# MCASP0_CFG register map
Vendor: Texas Instruments
Peripheral module from a debugger description file (folder am65x).
Registers are 32-bit, read-write, reset 0x0 unless marked. A register's access mark holds for its fields unless they carry their own. Offsets are as the file gives them; lines under a group give offsets from that group; [hi:lo] are bit positions; {n}, {i} and the like mark numbered series; 'fields as' and 'values as' point back to an identical list; <NAME> marks a mode.

## MCASP0_CFG
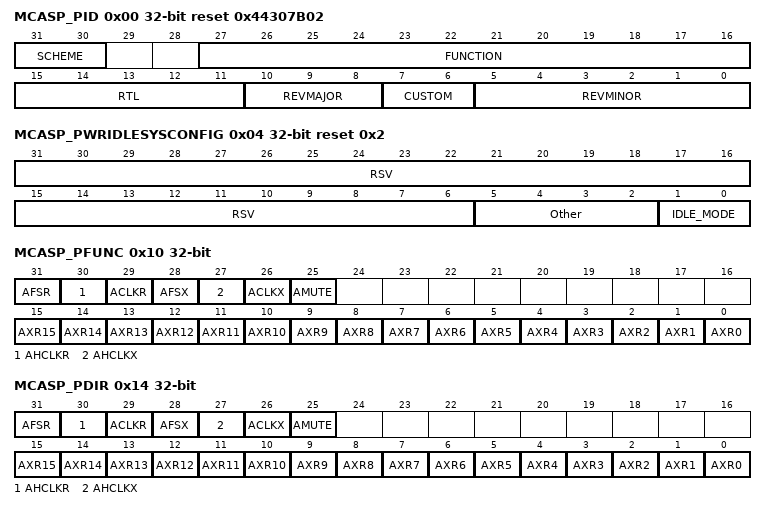
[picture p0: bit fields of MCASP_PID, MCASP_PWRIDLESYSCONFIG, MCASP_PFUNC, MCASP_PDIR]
0x00 MCASP_PID ro reset 0x44307B02
  [31:30] SCHEME
  [27:16] FUNCTION — McASP
  [15:11] RTL
  [10:8] REVMAJOR
  [7:6] CUSTOM — non-custom
  [5:0] REVMINOR
0x04 MCASP_PWRIDLESYSCONFIG access per field reset 0x2 — Power Idle SYSCONFIG register.
  [31:6] RSV ro — Reserved as per PDR 35
  [5:2] Other rw — Reserved for future expansion
  [1:0] IDLE_MODE rw
0x10 MCASP_PFUNC
  [31] AFSR — AFSR PFUNC 31
  [30] AHCLKR — AHCLKR PFUNC 30
  [29] ACLKR — ACLKR PFUNC 29
  [28] AFSX — AFSX PFUNC 28
  [27] AHCLKX — AHCLKX PFUNC 27
  [26] ACLKX — ACLKX PFUNC 26
  [25] AMUTE — AMUTE PFUNC 25
  [n] AXR{n} (n=0..15) — AXR PFUNC BIT {n}
0x14 MCASP_PDIR
  [31] AFSR — AFSR PDIR 31
  [30] AHCLKR — AHCLKR PDIR 30
  [29] ACLKR — ACLKR PDIR 29
  [28] AFSX — AFSX PDIR 28
  [27] AHCLKX — AHCLKX PDIR 27
  [26] ACLKX — ACLKX PDIR 26
  [25] AMUTE — AMUTE PDIR 25
  [n] AXR{n} (n=0..15) — AXR PDIR BIT {n}
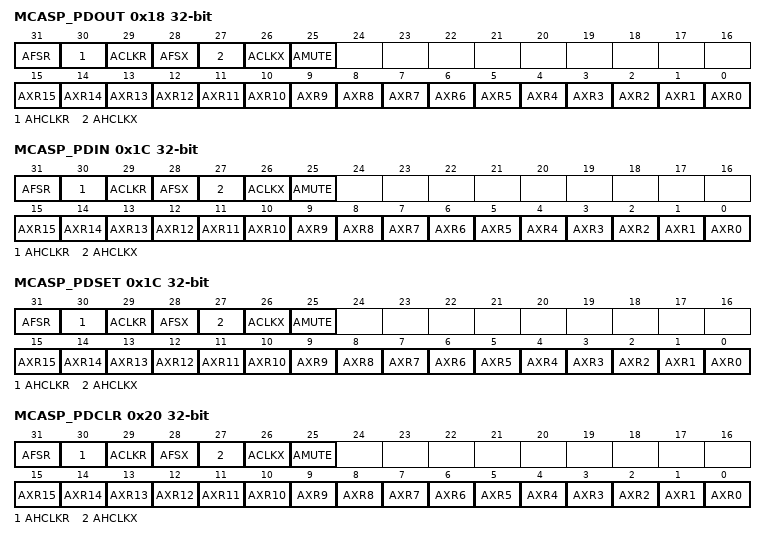
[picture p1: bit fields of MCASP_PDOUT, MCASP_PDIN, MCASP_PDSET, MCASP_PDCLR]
0x18 MCASP_PDOUT
  [31] AFSR — AFSR PDOUT 31
  [30] AHCLKR — AHCLKR PDOUT 30
  [29] ACLKR — ACLKR PDOUT 29
  [28] AFSX — AFSX PDOUT 28
  [27] AHCLKX — AHCLKX PDOUT 27
  [26] ACLKX — ACLKX PDOUT 26
  [25] AMUTE — AMUTE PDOUT 25
  [n] AXR{n} (n=0..15) — AXR PDOUT BIT {n}
0x1C MCASP_PDIN ro — The pin data input register (PDIN) holds the I/O pin state of each of the McASP pins. PDIN allows the actual value of the pin to be read, regardless of the state of PFUNC and PDIR.
  [31] AFSR — AFSR PDIN 31
  [30] AHCLKR — AHCLKR PDIN 30
  [29] ACLKR — ACLKR PDIN 29
  [28] AFSX — AFSX PDIN 28
  [27] AHCLKX — AHCLKX PDIN 27
  [26] ACLKX — ACLKX PDIN 26
  [25] AMUTE — AMUTE PDIN 25
  [n] AXR{n} (n=0..15) — AXR PDIN BIT {n}
0x1C MCASP_PDSET wo — The pin data set register (PDSET) is an alias of the pin data output register (PDOUT) for writes only. Writing a 1 to the PDSET bit sets the corresponding bit in PDOUT and, if PFUNC = 1 (GPIO function) and PDIR = 1 (output), drives a logic high on the pin.
  [31] AFSR — AFSR PDSET 31
  [30] AHCLKR — AHCLKR PDSET 30
  [29] ACLKR — ACLKR PDSET 29
  [28] AFSX — AFSX PDSET 28
  [27] AHCLKX — AHCLKX PDSET 27
  [26] ACLKX — ACLKX PDSET 26
  [25] AMUTE — AMUTE PDSET 25
  [n] AXR{n} (n=0..15) — AXR PDSET BIT {n}
0x20 MCASP_PDCLR — The pin data clear register (PDCLR) is an alias of the pin data output register (PDOUT) for writes only. Writing a 1 to the PDCLR bit clears the corresponding bit in PDOUT and, if PFUNC = 1 (GPIO function) and PDIR = 1 (output), drives a logic low on the pin.
  [31] AFSR — AFSR PDCLR 31
  [30] AHCLKR — AHCLKR PDCLR 30
  [29] ACLKR — ACLKR PDCLR 29
  [28] AFSX — AFSX PDCLR 28
  [27] AHCLKX — AHCLKX PDCLR 27
  [26] ACLKX — ACLKX PDCLR 26
  [25] AMUTE — AMUTE PDCLR 25
  [n] AXR{n} (n=0..15) — AXR PDCLR BIT {n}
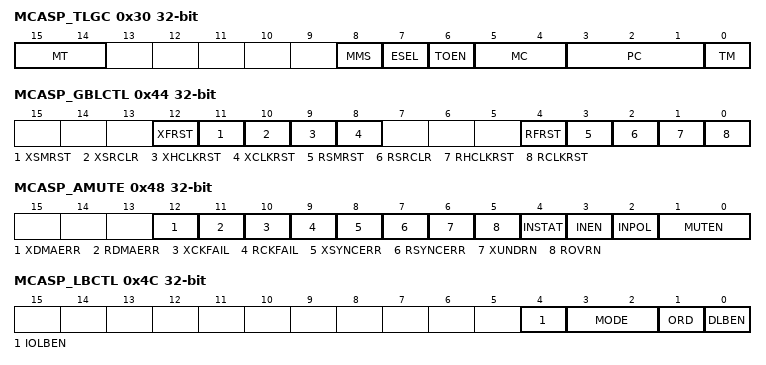
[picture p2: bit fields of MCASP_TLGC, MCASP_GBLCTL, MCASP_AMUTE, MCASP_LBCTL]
0x30 MCASP_TLGC — for IODFT
  [15:14] MT — MISR on/off trigger command
  [8] MMS — Source of MISR input
  [7] ESEL — Output enable select
  [6] TOEN — Test output enable control
  [5:4] MC — States of MISR
  [3:1] PC — Pattern code
  [0] TM — Tie high; do not write to this bit
0x34 MCASP_TLMR — for IODFT
  [31:0] TLMR — Contains test result signature
0x38 MCASP_TLEC — for IODFT
  [31:0] TLEC — Contains number of cycles during which MISR sig will be accumulated
0x44 MCASP_GBLCTL
  [12] XFRST — Frame sync generator reset
  [11] XSMRST — XMT state machine reset
  [10] XSRCLR — XMT serializer clear
  [9] XHCLKRST — XMT High Freq clk Divider
  [8] XCLKRST — XMT clock divder reset
  [4] RFRST — Frame sync generator reset
  [3] RSMRST — RCV state machine reset
  [2] RSRCLR — RCV serializer clear
  [1] RHCLKRST — RCV High Freq clk Divider
  [0] RCLKRST — RCV clock divder reset
0x48 MCASP_AMUTE access per field
  [12] XDMAERR rw — MUTETXDMAERR occur
  [11] RDMAERR rw — MUTERXDMAERR occur
  [10] XCKFAIL rw — XMT bad clock
  [9] RCKFAIL rw — RCV bad clock
  [8] XSYNCERR rw — XMT unexpected FS
  [7] RSYNCERR rw — RCV unexpected FS
  [6] XUNDRN rw — XMT underrun occurs
  [5] ROVRN rw — RCV overun occurs
  [4] INSTAT ro — status of mute in pin
  [3] INEN rw — drive AMUTE active on mute in active
  [2] INPOL rw — Mute input polarity
  [1:0] MUTEN rw — AMUTE pin enable
0x4C MCASP_LBCTL
  [4] IOLBEN — IO loopback enable
  [3:2] MODE — Loop back clock source generator
  [1] ORD — Loopback order
  [0] DLBEN — Loop back mode
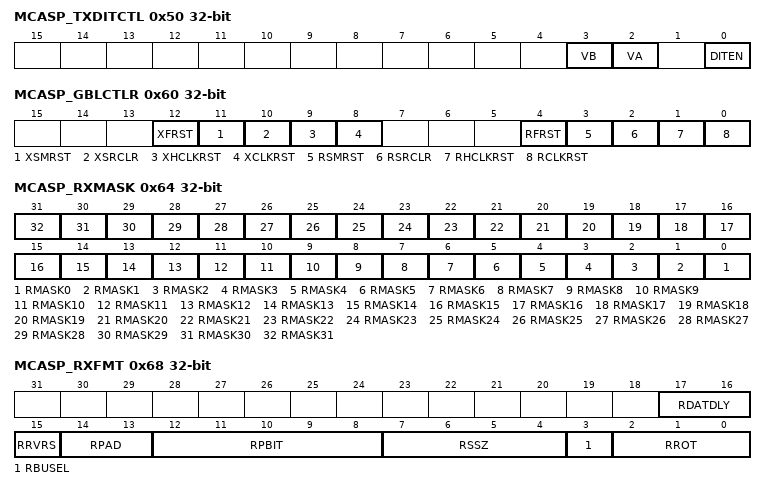
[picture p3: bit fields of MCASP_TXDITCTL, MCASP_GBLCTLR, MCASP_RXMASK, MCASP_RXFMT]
0x50 MCASP_TXDITCTL
  [3] VB — Valib bit for odd TDM
  [2] VA — Valib bit for even TDM
  [0] DITEN — XMT DIT Mode Enable
0x60 MCASP_GBLCTLR access per field
  [12] XFRST ro — Frame sync generator reset
  [11] XSMRST ro — XMT state machine reset
  [10] XSRCLR ro — XMT serializer clear
  [9] XHCLKRST ro — XMT High Freq clk Divider
  [8] XCLKRST ro — XMT clock divder reset
  [4] RFRST rw — Frame sync generator reset
  [3] RSMRST rw — RCV state machine reset
  [2] RSRCLR rw — RCV serializer clear
  [1] RHCLKRST rw — RCV High Freq clk Divider
  [0] RCLKRST rw — RCV clock divder reset
0x64 MCASP_RXMASK
  [n] RMASK{n} (n=0..31) — RMASK BIT {n}
0x68 MCASP_RXFMT
  [17:16] RDATDLY — RCV Frame sync delay
  [15] RRVRS — RCV serial stream bit order
  [14:13] RPAD — Pad value
  [12:8] RPBIT — Pad bit position
  [7:4] RSSZ — RCV slot Size
  [3] RBUSEL — Write to RBUF using CPU/DMA
  [2:0] RROT — Right Rotate Value
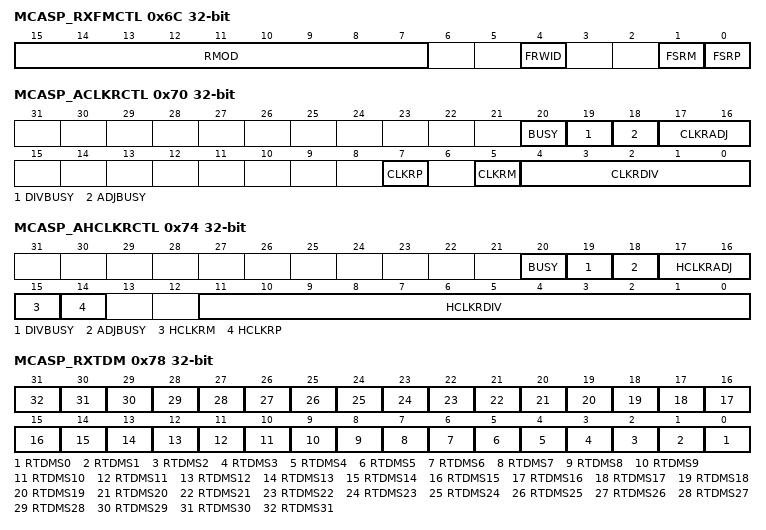
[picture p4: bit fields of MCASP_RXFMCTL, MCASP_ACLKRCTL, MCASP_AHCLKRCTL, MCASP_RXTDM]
0x6C MCASP_RXFMCTL
  [15:7] RMOD — RCV Frame sync mode
  [4] FRWID — RCV Frame sync Duration
  [1] FSRM — RCV frame sync External
  [0] FSRP — RCV Frame sync Polarity
0x70 MCASP_ACLKRCTL access per field
  [20] BUSY rw — Status: logical OR of DIVBUSY, ADJBUSY
  [19] DIVBUSY rw — Status: divide ratio change in progress?
  [18] ADJBUSY rw — Status: one-shot adjustment in progress?
  [17:16] CLKRADJ wo — CLKRDIV one-shot adjustment
  [7] CLKRP rw — RCV Clock Polarity
  [5] CLKRM rw — RCV clock source
  [4:0] CLKRDIV rw — RCV clock devide ratio
0x74 MCASP_AHCLKRCTL access per field
  [20] BUSY rw — Status: logical OR of DIVBUSY, ADJBUSY
  [19] DIVBUSY rw — Status: divide ratio change in progress?
  [18] ADJBUSY rw — Status: one-shot adjustment in progress?
  [17:16] HCLKRADJ wo — HCLKRDIV one-shot adjustment
  [15] HCLKRM rw — High Freq RCV clock Source
  [14] HCLKRP rw — High Freq clock Polarity Before diviser
  [11:0] HCLKRDIV rw — RCV clock Divide Ratio
0x78 MCASP_RXTDM
  [n] RTDMS{n} (n=0..31) — RCV mode during TDM time slot {n}
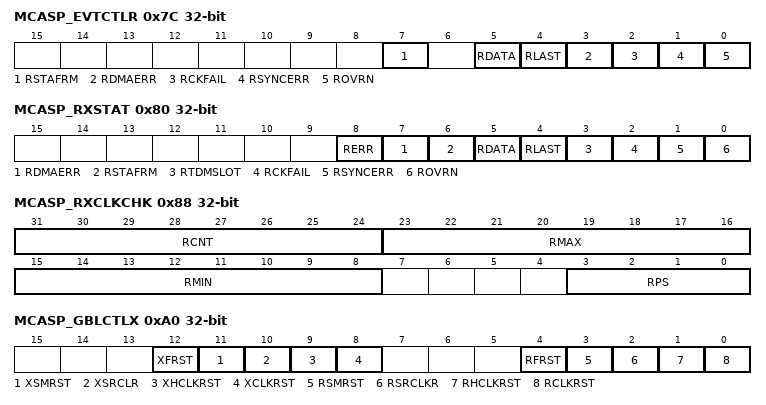
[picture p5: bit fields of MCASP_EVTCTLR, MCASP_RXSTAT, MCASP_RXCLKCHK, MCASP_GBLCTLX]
0x7C MCASP_EVTCTLR
  [7] RSTAFRM — RCV Start of Frame Interrupt
  [5] RDATA — RCV Data Interrupt
  [4] RLAST — RCV Last Slot Interrupt
  [3] RDMAERR — RCV DMA Bus Error
  [2] RCKFAIL — Bad Clock Interrupt
  [1] RSYNCERR — RCV Unexpected FSR Interrupt
  [0] ROVRN — RCV Underrun Flag
0x80 MCASP_RXSTAT
  [8] RERR — RCV Error
  [7] RDMAERR — RCV DMA bus error
  [6] RSTAFRM — Start of Frame-RCV
  [5] RDATA — Data Ready Flag
  [4] RLAST — Last Slot Interrupt Flag
  [3] RTDMSLOT — EvenOdd Slot
  [2] RCKFAIL — Bad Transmit Flag
  [1] RSYNCERR — Unexpected RCV Frame sync flag
  [0] ROVRN — RCV Underrun Flag
0x84 MCASP_RXTDMSLOT ro
  [9:0] RSLOTCNT — Current RCV time slot count
0x88 MCASP_RXCLKCHK access per field
  [31:24] RCNT ro — RCV clock count value
  [23:16] RMAX rw — RCV clock maximum boundary
  [15:8] RMIN rw — RCV clock minimum boundary
  [3:0] RPS rw — RCV clock check prescaler
0x8C MCASP_REVTCTL
  [0] RDATDMA — RCV data DMA request
0xA0 MCASP_GBLCTLX access per field
  [12] XFRST rw — Frame sync generator reset
  [11] XSMRST rw — XMT state machine reset
  [10] XSRCLR rw — XMT serializer clear
  [9] XHCLKRST rw — XMT High Freq clk Divider
  [8] XCLKRST rw — XMT clock divder reset
  [4] RFRST ro — Frame sync generator reset
  [3] RSMRST ro — RCV state machine reset
  [2] RSRCLKR ro — RCV serializer clear
  [1] RHCLKRST ro — RCV High Freq clk Divider
  [0] RCLKRST ro — RCV clock divder reset
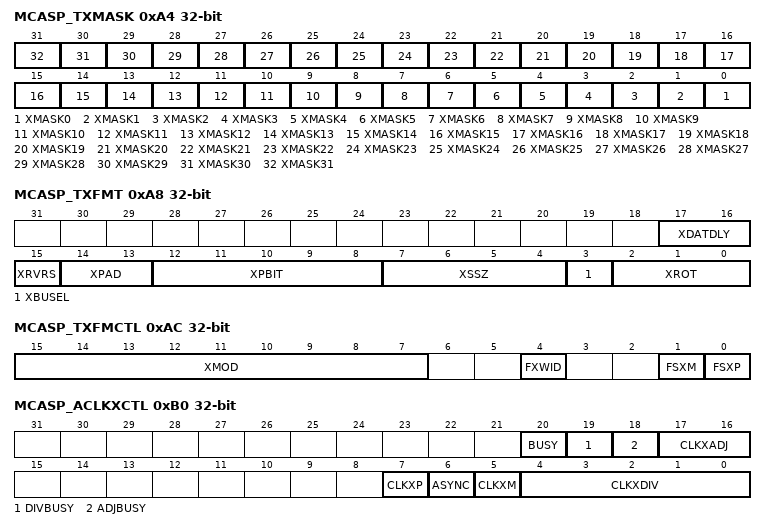
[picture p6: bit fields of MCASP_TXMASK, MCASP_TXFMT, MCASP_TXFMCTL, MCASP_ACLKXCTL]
0xA4 MCASP_TXMASK
  [n] XMASK{n} (n=0..31) — XMASK BIT {n}
0xA8 MCASP_TXFMT
  [17:16] XDATDLY — XMT Frame sync delay
  [15] XRVRS — XMT serial stream bit order
  [14:13] XPAD — Pad value
  [12:8] XPBIT — Pad bit position
  [7:4] XSSZ — XMT slot Size
  [3] XBUSEL — Write to XBUF using CPU/DMA
  [2:0] XROT — Right Rotate Value
0xAC MCASP_TXFMCTL
  [15:7] XMOD — XMT Frame sync mode
  [4] FXWID — XMT Frame sync Duration
  [1] FSXM — XMT frame sync External
  [0] FSXP — XMT Frame sync Polarity
0xB0 MCASP_ACLKXCTL access per field
  [20] BUSY rw — Status: logical OR of DIVBUSY, ADJBUSY
  [19] DIVBUSY rw — Status: divide ratio change in progress?
  [18] ADJBUSY rw — Status: one-shot adjustment in progress?
  [17:16] CLKXADJ wo — CLKXDIV one-shot adjustment
  [7] CLKXP rw — XMT Clock Polarity
  [6] ASYNC rw — XMT/RCV operation sync /Async
  [5] CLKXM rw — XMT clock source
  [4:0] CLKXDIV rw — XMT clock devide ratio
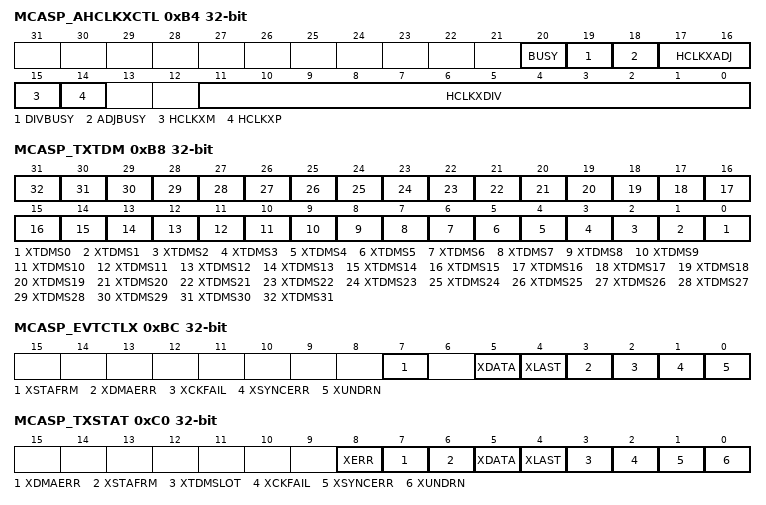
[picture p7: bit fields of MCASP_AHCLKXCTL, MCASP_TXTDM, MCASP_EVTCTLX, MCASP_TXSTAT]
0xB4 MCASP_AHCLKXCTL access per field
  [20] BUSY rw — Status: logical OR of DIVBUSY, ADJBUSY
  [19] DIVBUSY rw — Status: divide ratio change in progress?
  [18] ADJBUSY rw — Status: one-shot adjustment in progress?
  [17:16] HCLKXADJ wo — HCLKXDIV one-shot adjustment
  [15] HCLKXM rw — High Freq XMT clock Source
  [14] HCLKXP rw — High Freq clock Polarity Before diviser
  [11:0] HCLKXDIV rw — XMT clock Divide Ratio
0xB8 MCASP_TXTDM
  [n] XTDMS{n} (n=0..31) — XMT mode during TDM time slot {n}
0xBC MCASP_EVTCTLX
  [7] XSTAFRM — XMT Start of Frame Interrupt
  [5] XDATA — XMT Data Interrupt
  [4] XLAST — XMT Last Slot Interrupt
  [3] XDMAERR — XMT DMA Bus Error
  [2] XCKFAIL — Bad Clock Interrupt
  [1] XSYNCERR — XMT Unexpected FSR Interrupt
  [0] XUNDRN — XMT Underrun Interrupt
0xC0 MCASP_TXSTAT
  [8] XERR — XMT Error
  [7] XDMAERR — XMT DMA bus error
  [6] XSTAFRM — Start of Frame-XMT
  [5] XDATA — Data Ready Flag
  [4] XLAST — Last Slot Interrupt Flag
  [3] XTDMSLOT — EvenOdd Slot
  [2] XCKFAIL — Bad Transmit Flag
  [1] XSYNCERR — Unexpected XMT Frame sync flag
  [0] XUNDRN — XMT Underrun Flag
0xC4 MCASP_TXTDMSLOT ro
  [9:0] XSLOTCNT — Current XMT time slot count during reset the value of this register is 0b0101111111 [0x17f] and after reset 0
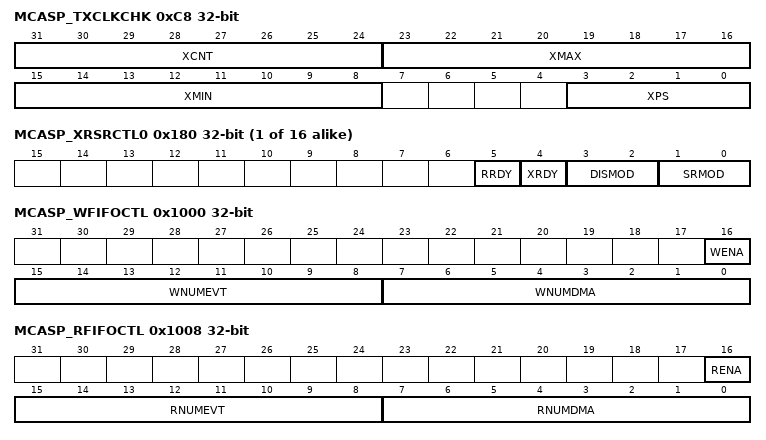
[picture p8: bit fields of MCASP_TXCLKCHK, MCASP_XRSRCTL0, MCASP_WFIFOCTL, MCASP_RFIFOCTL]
0xC8 MCASP_TXCLKCHK access per field
  [31:24] XCNT ro — XMT clock count value
  [23:16] XMAX rw — XMT clock maximum boundary
  [15:8] XMIN rw — XMT clock minimum boundary
  [3:0] XPS rw — XMT clock check prescaler
0xCC MCASP_XEVTCTL
  [0] XDATDMA — XMT data DMA request
0xD0 MCASP_CLKADJEN
  [0] ENABLE — One-shot clock adjust enable
0x100 MCASP_DITCSRA0
  [31:0] DITCSRA0 — Left [Even TDM slot ] Channel status
0x104 MCASP_DITCSRA1
  [31:0] DITCSRA1 — Left [Even TDM slot ] Channel status
0x108 MCASP_DITCSRA2
  [31:0] DITCSRA2 — Left [Even TDM slot ] Channel status Register
0x10C MCASP_DITCSRA3
  [31:0] DITCSRA3 — Left [Even TDM slot ] Channel status Register
0x110 MCASP_DITCSRA4
  [31:0] DITCSRA4 — Left [Even TDM slot ] Channel status
0x114 MCASP_DITCSRA5
  [31:0] DITCSRA5 — Left [Even TDM slot ] Channel status
{0x118+4i} MCASP_DITCSRB{i} (i=0..5)
  [31:0] DITCSRB{i} — Right [odd TDM slot ] Channel status
{0x130+4i} MCASP_DITUDRA{i} (i=0..5)
  [31:0] DITUDRA{i} — Left [Even TDM slot ] User Data
{0x148+4i} MCASP_DITUDRB{i} (i=0..5)
  [31:0] DITUDRB{i} — Right [odd TDM slot ] User Data
{0x180+4i} MCASP_XRSRCTL{i} access per field (i=0..15)
  [5] RRDY ro — Receive buffer ready
  [4] XRDY ro — Transmit buffer ready
  [3:2] DISMOD rw — Serializer drive state
  [1:0] SRMOD rw — Serializer Mode
{0x200+4i} MCASP_TXBUF{i} (i=0..15)
  [31:0] XBUF{i} — Transmit Buffer {i}
{0x280+4i} MCASP_RXBUF{i} (i=0..15)
  [31:0] RBUF{i} — Receive Buffer {i}
0x1000 MCASP_WFIFOCTL access per field — The WNUMEVT and WNUMDMA values must be set prior to enabling the Write FIFO. If the Write FIFO is to be enabled, it must be enabled prior to taking the McASP out of reset
  [16] WENA rw — Write FIFO enable bit. 0h (R/W) = Write FIFO is disabled. The WLVL bit in the Write FIFO status register ( 1h (R/W) = Write FIFO is enabled. If Write FIFO is to be enabled, it must be enabled prior to taking McASP out of reset.
  [15:8] WNUMEVT rw — Write word count per DMA event (32 bit). When the Write FIFO has space for at least WNUMEVT words of data, then an AXEVT (transmit DMA event) is generated to the host/DMA controller. This value should be set to a non-zero integer multiple of the number of serializers enabled as transmitters. This value must be set prior to enabling the Write FIFO. 40h = 3 to 64 words from 3h to 40h. FFh = Reserved from 41h to FFh. 0h (R/W) = 0 words 1h (R/W) = 1 word 2h (R/W) = 2 words 3h (R/W) = 3 to 64 words from 3h to 40h. 41h (R/W) = Reserved from 41h to FFh.
  [7:0] WNUMDMA rw — Write word count per transfer (32 bit words). Upon a transmit DMA event from the McASP, WNUMDMA words are transferred from the Write FIFO to the McASP. This value must equal the number of McASP serializers used as transmitters. This value must be set prior to enabling the Write FIFO. FFh = Reserved from 11h to FFh. 0h (R/W) = 0 words 1h (R/W) = 1 word 2h (R/W) = 2 words 3h (R/W) = 3-16 words from 3h to 10h. 11h (R/W) = Reserved from 11h to FFh.
0x1004 MCASP_WFIFOSTS ro
  [7:0] WLVL — Write level (read-only). Number of 32 bit words currently in the Write FIFO. 40h = 3 to 64 words currently in Write FIFO from 3h to 40h. FFh = Reserved from 41h to FFh. 0h (R/W) = 0 words currently in Write FIFO. 1h (R/W) = 1 word currently in Write FIFO. 2h (R/W) = 2 words currently in Write FIFO. 3h (R/W) = 3 to 64 words currently in Write FIFO from 3h to 40h. 41h (R/W) = Reserved from 41h to FFh.
0x1008 MCASP_RFIFOCTL access per field — The RNUMEVT and RNUMDMA values must be set prior to enabling the Read FIFO. If the Read FIFO is to be enabled, it must be enabled prior to taking the McASP out of reset
  [16] RENA rw — Read FIFO enable bit. 0h (R/W) = Read FIFO is disabled. The RLVL bit in the Read FIFO status register ( 1h (R/W) = Read FIFO is enabled. If Read FIFO is to be enabled, it must be enabled prior to taking McASP out of reset.
  [15:8] RNUMEVT rw — Read word count per DMA event (32 bit). When the Read FIFO contains at least RNUMEVT words of data, then an AREVT (receive DMA event) is generated to the host/DMA controller. This value should be set to a non-zero integer multiple of the number of serializers enabled as receivers. This value must be set prior to enabling the Read FIFO. 40h = 3 to 64 words from 3h to 40h. FFh = Reserved from 41h = FFh. 0h (R/W) = 0 words 1h (R/W) = 1 word 2h (R/W) = 2 words 3h (R/W) = 3 to 64 words from 3h to 40h. 41h (R/W) = Reserved from 41h to FFh.
  [7:0] RNUMDMA rw — Read word count per transfer (32 bit words). Upon a receive DMA event from the McASP, the Read FIFO reads RNUMDMA words from the McASP. This value must equal the number of McASP serializers used as receivers. This value must be set prior to enabling the Read FIFO. 10h = 3 to 16 words from 3h to 10h. FFh = Reserved from 11h to FFh. 0h (R/W) = 0 words 1h (R/W) = 1 word 2h (R/W) = 2 words 3h (R/W) = 3 to 16 words from 3h to 10h. 11h (R/W) = Reserved from 11h to FFh.
0x100C MCASP_RFIFOSTS ro
  [7:0] RLVL — Read level (read-only). Number of 32 bit words currently in the Read FIFO. 40h = 3 to 64 words currently in Read FIFO from 3h to 40h. FFh = Reserved from 41h to FFh. 0h (R/W) = 0 words currently in Read FIFO. 1h (R/W) = 1 word currently in Read FIFO. 2h (R/W) = 2 words currently in Read FIFO. 3h (R/W) = 3 to 64 words currently in Read FIFO from 3h to 40h. 41h (R/W) = Reserved from 41h to FFh.
